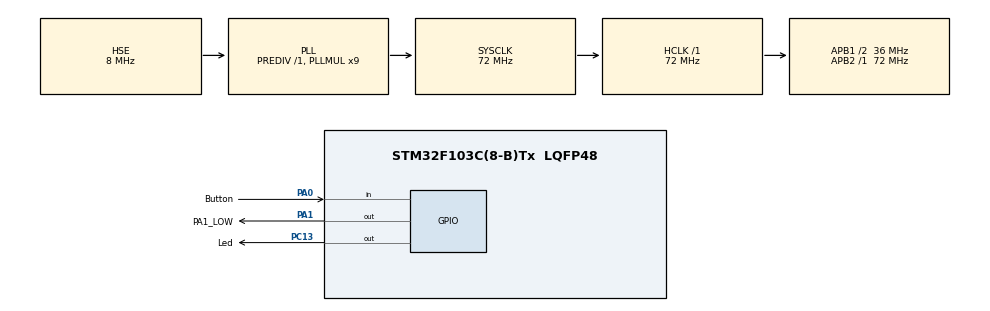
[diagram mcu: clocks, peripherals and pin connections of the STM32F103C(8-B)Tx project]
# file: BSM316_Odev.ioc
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Mcu.Family=STM32F1
Mcu.Name=STM32F103C(8-B)Tx
Mcu.Package=LQFP48
NVIC.PriorityGroup=NVIC_PRIORITYGROUP_4
NVIC.TIM2_IRQn=true\:0\:0\:false\:false\:true\:true\:true\:true
PA0-WKUP.GPIO_Label=Button
PA0-WKUP.GPIO_PuPd=GPIO_PULLUP
PA0-WKUP.Signal=GPIO_Input
PA1.GPIO_Label=PA1_LOW
PA1.Signal=GPIO_Output
PA13.Mode=Serial_Wire
PA13.Signal=SYS_JTMS-SWDIO
PA14.Mode=Serial_Wire
PA14.Signal=SYS_JTCK-SWCLK
PC13-TAMPER-RTC.GPIO_Label=Led
PC13-TAMPER-RTC.PinState=GPIO_PIN_SET
PC13-TAMPER-RTC.Signal=GPIO_Output
PD0-OSC_IN.Mode=HSE-External-Oscillator
PD0-OSC_IN.Signal=RCC_OSC_IN
PD1-OSC_OUT.Mode=HSE-External-Oscillator
PD1-OSC_OUT.Signal=RCC_OSC_OUT
ProjectManager.HeapSize=0x200
ProjectManager.StackSize=0x400
ProjectManager.TargetToolchain=STM32CubeIDE
RCC.AHBFreq_Value=72000000
RCC.APB1CLKDivider=RCC_HCLK_DIV2
RCC.APB1Freq_Value=36000000
RCC.APB1TimFreq_Value=72000000
RCC.APB2Freq_Value=72000000
RCC.APB2TimFreq_Value=72000000
RCC.HCLKFreq_Value=72000000
RCC.PLLMUL=RCC_PLL_MUL9
RCC.PLLSourceVirtual=RCC_PLLSOURCE_HSE
RCC.SYSCLKFreq_VALUE=72000000
RCC.SYSCLKSource=RCC_SYSCLKSOURCE_PLLCLK
RCC.USBFreq_Value=72000000
TIM2.Period=9999
TIM2.Prescaler=7199
VP_TIM2_VS_ClockSourceINT.Mode=Internal
board=custom

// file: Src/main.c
/* USER CODE BEGIN Header */
/**
  ******************************************************************************
  * @file           : main.c
  * @brief          : Main program body
  ******************************************************************************
  * @attention
  *
  * Copyright (c) 2026 STMicroelectronics.
  * All rights reserved.
  *
  * This software is licensed under terms that can be found in the LICENSE file
  * in the root directory of this software component.
  * If no LICENSE file comes with this software, it is provided AS-IS.
  *
  ******************************************************************************
  */
/* USER CODE END Header */

#include "main.h"
#include "tim.h"
#include "gpio.h"

/* USER CODE BEGIN PTD */

typedef enum
{
  BLINK_STATE_BLINKING = 0,
  BLINK_STATE_WAITING  = 1
} BlinkState_t;

/* USER CODE END PTD */

/* USER CODE BEGIN PD */

#define LED_PORT        GPIOC
#define LED_PIN         GPIO_PIN_13

#define BUTTON_PORT     GPIOA
#define BUTTON_PIN      GPIO_PIN_0

#define PA1_LOW_PORT    GPIOA
#define PA1_LOW_PIN     GPIO_PIN_1

#define BUTTON_PRESSED  GPIO_PIN_RESET

#define BLINK_MIN       4
#define BLINK_MAX       7
#define DEFAULT_BLINK   4

/*
 * STM32F103C8T6 için Flash başlangıcı: 0x08000000
 * 64 KB Flash son sayfa başlangıcı: 0x0800FC00
 * Son sayfayı blink_count saklamak için kullanıyoruz.
 */
#define FLASH_BLINK_COUNT_ADDR  ((uint32_t)0x0800FC00)

/* USER CODE END PD */

/* USER CODE BEGIN PV */

volatile uint16_t blink_count = DEFAULT_BLINK;

volatile uint16_t completed_blinks = 0;
volatile uint8_t led_is_on = 0;
volatile uint8_t wait_seconds = 0;
volatile BlinkState_t blink_state = BLINK_STATE_BLINKING;

GPIO_PinState button_last_raw = GPIO_PIN_SET;
GPIO_PinState button_stable_state = GPIO_PIN_SET;
uint32_t button_last_change_tick = 0;

/* USER CODE END PV */

void SystemClock_Config(void);

/* USER CODE BEGIN PFP */

void LED_On(void);
void LED_Off(void);

uint16_t Flash_ReadBlinkCount(void);
void Flash_WriteBlinkCount(uint16_t value);

uint8_t Button_IsPressed(void);
uint8_t Button_HeldForMs(uint32_t hold_ms);
void Button_InitDebounceState(void);
void Button_Process(void);

void BlinkCount_Increase(void);

/* USER CODE END PFP */

int main(void)
{

  /* MCU Configuration--------------------------------------------------------*/

  HAL_Init();

  SystemClock_Config();

  MX_GPIO_Init();
  MX_TIM2_Init();

  /* USER CODE BEGIN 2 */

  /*
   * PA1 pini ödevde istendiği gibi sürekli lojik 0 kalacak.
   */
  HAL_GPIO_WritePin(PA1_LOW_PORT, PA1_LOW_PIN, GPIO_PIN_RESET);

  /*
   * Bluepill kartında PC13 LED genelde aktif LOW çalışır.
   * GPIO_PIN_SET   -> LED sönük
   * GPIO_PIN_RESET -> LED yanık
   */
  LED_Off();

  /*
   * Yazılım başlarken buton basılıysa ve 3 saniye boyunca basılı tutulursa
   * fabrika ayarına dönülür: blink_count = 4
   */
  if (Button_IsPressed() && Button_HeldForMs(3000))
  {
    blink_count = DEFAULT_BLINK;
    Flash_WriteBlinkCount(blink_count);
  }
  else
  {
    /*
     * Normal açılışta blink_count Flash'tan okunur.
     */
    blink_count = Flash_ReadBlinkCount();

    /*
     * Flash boşsa genelde 0xFFFF okunur.
     * 4-7 arası dışında değer varsa geçersiz kabul edilir.
     */
    if (blink_count < BLINK_MIN || blink_count > BLINK_MAX)
    {
      blink_count = DEFAULT_BLINK;
      Flash_WriteBlinkCount(blink_count);
    }
  }

  /*
   * Açılışta buton basılı kaldıysa,
   * bu basış normal buton basışı olarak sayılmasın.
   */
  Button_InitDebounceState();

  completed_blinks = 0;
  wait_seconds = 0;
  blink_state = BLINK_STATE_BLINKING;
  LED_Off();

  /*
   * TIM2 interrupt başlatılır.
   * CubeMX ayarıyla TIM2 her 1 saniyede 1 interrupt üretir.
   */
  HAL_TIM_Base_Start_IT(&htim2);

  /* USER CODE END 2 */

  /* Infinite loop */
  while (1)
  {

    /* USER CODE BEGIN 3 */

    /*
     * Buton kontrolü ana döngüde yapılır.
     * Buton basılı tutulsa bile sadece 1 kez artırır.
     */
    Button_Process();

    /*
     * PA1 program boyunca LOW kalsın.
     */
    HAL_GPIO_WritePin(PA1_LOW_PORT, PA1_LOW_PIN, GPIO_PIN_RESET);

    /* USER CODE END 3 */
  }
}

void SystemClock_Config(void)
{
  RCC_OscInitTypeDef RCC_OscInitStruct = {0};
  RCC_ClkInitTypeDef RCC_ClkInitStruct = {0};

  /** Initializes the RCC Oscillators according to the specified parameters
  * in the RCC_OscInitTypeDef structure.
  */
  RCC_OscInitStruct.OscillatorType = RCC_OSCILLATORTYPE_HSE;
  RCC_OscInitStruct.HSEState = RCC_HSE_ON;
  RCC_OscInitStruct.HSEPredivValue = RCC_HSE_PREDIV_DIV1;
  RCC_OscInitStruct.HSIState = RCC_HSI_ON;
  RCC_OscInitStruct.PLL.PLLState = RCC_PLL_ON;
  RCC_OscInitStruct.PLL.PLLSource = RCC_PLLSOURCE_HSE;
  RCC_OscInitStruct.PLL.PLLMUL = RCC_PLL_MUL9;

  if (HAL_RCC_OscConfig(&RCC_OscInitStruct) != HAL_OK)
  {
    Error_Handler();
  }

  /** Initializes the CPU, AHB and APB buses clocks
  */
  RCC_ClkInitStruct.ClockType = RCC_CLOCKTYPE_HCLK | RCC_CLOCKTYPE_SYSCLK
                              | RCC_CLOCKTYPE_PCLK1 | RCC_CLOCKTYPE_PCLK2;
  RCC_ClkInitStruct.SYSCLKSource = RCC_SYSCLKSOURCE_PLLCLK;
  RCC_ClkInitStruct.AHBCLKDivider = RCC_SYSCLK_DIV1;
  RCC_ClkInitStruct.APB1CLKDivider = RCC_HCLK_DIV2;
  RCC_ClkInitStruct.APB2CLKDivider = RCC_HCLK_DIV1;

  if (HAL_RCC_ClockConfig(&RCC_ClkInitStruct, FLASH_LATENCY_2) != HAL_OK)
  {
    Error_Handler();
  }
}

/* USER CODE BEGIN 4 */

void LED_On(void)
{
  /*
   * PC13 LED aktif LOW.
   */
  HAL_GPIO_WritePin(LED_PORT, LED_PIN, GPIO_PIN_RESET);
  led_is_on = 1;
}

void LED_Off(void)
{
  /*
   * PC13 LED aktif LOW.
   */
  HAL_GPIO_WritePin(LED_PORT, LED_PIN, GPIO_PIN_SET);
  led_is_on = 0;
}

uint16_t Flash_ReadBlinkCount(void)
{
  return *(__IO uint16_t *)FLASH_BLINK_COUNT_ADDR;
}

void Flash_WriteBlinkCount(uint16_t value)
{
  FLASH_EraseInitTypeDef erase_init;
  uint32_t page_error = 0;

  HAL_FLASH_Unlock();

  erase_init.TypeErase = FLASH_TYPEERASE_PAGES;
  erase_init.PageAddress = FLASH_BLINK_COUNT_ADDR;
  erase_init.NbPages = 1;

  if (HAL_FLASHEx_Erase(&erase_init, &page_error) == HAL_OK)
  {
    HAL_FLASH_Program(FLASH_TYPEPROGRAM_HALFWORD,
                      FLASH_BLINK_COUNT_ADDR,
                      value);
  }

  HAL_FLASH_Lock();
}

uint8_t Button_IsPressed(void)
{
  if (HAL_GPIO_ReadPin(BUTTON_PORT, BUTTON_PIN) == BUTTON_PRESSED)
  {
    return 1;
  }

  return 0;
}

uint8_t Button_HeldForMs(uint32_t hold_ms)
{
  uint32_t start_tick = HAL_GetTick();

  while ((HAL_GetTick() - start_tick) < hold_ms)
  {
    if (!Button_IsPressed())
    {
      return 0;
    }
  }

  return 1;
}

void Button_InitDebounceState(void)
{
  GPIO_PinState current_state;

  current_state = HAL_GPIO_ReadPin(BUTTON_PORT, BUTTON_PIN);

  button_last_raw = current_state;
  button_stable_state = current_state;
  button_last_change_tick = HAL_GetTick();
}

void Button_Process(void)
{
  GPIO_PinState current_raw;

  current_raw = HAL_GPIO_ReadPin(BUTTON_PORT, BUTTON_PIN);

  /*
   * Ham buton durumu değiştiyse debounce süresi başlatılır.
   */
  if (current_raw != button_last_raw)
  {
    button_last_raw = current_raw;
    button_last_change_tick = HAL_GetTick();
  }

  /*
   * 50 ms debounce.
   */
  if ((HAL_GetTick() - button_last_change_tick) >= 50)
  {
    if (current_raw != button_stable_state)
    {
      button_stable_state = current_raw;

      /*
       * Sadece butona basıldığı anda 1 kez artır.
       * Buton basılı tutulursa tekrar tekrar artırmaz.
       */
      if (button_stable_state == BUTTON_PRESSED)
      {
        BlinkCount_Increase();
      }
    }
  }
}

void BlinkCount_Increase(void)
{
  if (blink_count < BLINK_MAX)
  {
    blink_count++;
  }
  else
  {
    blink_count = BLINK_MIN;
  }

  /*
   * blink_count her değiştiğinde Flash'a yazılır.
   */
  Flash_WriteBlinkCount(blink_count);
}

void HAL_TIM_PeriodElapsedCallback(TIM_HandleTypeDef *htim)
{
  if (htim->Instance == TIM2)
  {
    if (blink_state == BLINK_STATE_BLINKING)
    {
      /*
       * Blink aşaması.
       * TIM2 her 1 saniyede 1 interrupt üretir.
       */
      if (led_is_on == 0)
      {
        LED_On();
      }
      else
      {
        LED_Off();
        completed_blinks++;

        /*
         * blink_count kadar yanıp söndükten sonra
         * 5 saniye sönük bekleme aşamasına geçilir.
         */
        if (completed_blinks >= blink_count)
        {
          completed_blinks = 0;
          wait_seconds = 0;
          blink_state = BLINK_STATE_WAITING;
          LED_Off();
        }
      }
    }
    else
    {
      /*
       * 5 saniye sönük bekleme aşaması.
       */
      LED_Off();
      wait_seconds++;

      if (wait_seconds >= 5)
      {
        wait_seconds = 0;
        blink_state = BLINK_STATE_BLINKING;
      }
    }
  }
}

/* USER CODE END 4 */

void Error_Handler(void)
{
  __disable_irq();
  while (1)
  {
  }
}
